# pse84 register map
Vendor: Cypress Semiconductor; Series: PSE84; File version: 1.0
CPU: CM33 r0p1, little endian, MPU, FPU, VTOR, 3 interrupt priority bits
Registers are 32-bit, read-write, reset 0x0 unless marked. A register's access mark holds for its fields unless they carry their own. Offsets are from the block's base; [hi:lo] are bit positions; lines under a group give offsets from that group; {n}, {i} and the like mark numbered series; 'fields as' and 'values as' point back to an identical list; <NAME> marks a mode.

## RTC — SRSS RTC Registers
Base 0x42420000
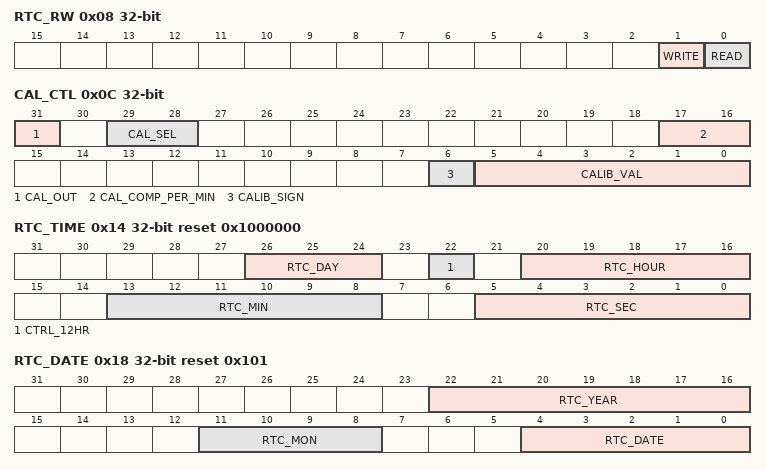
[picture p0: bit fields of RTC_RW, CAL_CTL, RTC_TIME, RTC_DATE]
0x08 RTC_RW — RTC Read Write register
  [1] WRITE — Write bit Only when this bit is set can the RTC registers be written to (otherwise writes are ignored). This bit cannot be set if the RTC is still busy with a previous update (see RTC_BUSY bit) or if the Read bit is set or getting set. The user writes to the RTC user registers, when the Write bit is cleared by the user then the user registers content is copied to the actual RTC registers. Only user RTC registers that were written to will get copied, others will not be affected. When the SECONDS field is updated then TICKS will also be reset (WDT is not affected). When the Write bit is cleared by a reset (brown out/DeepSleep) then the RTC update will be ignored/lost. Do not set the Write bit if the RTC if the RTC is still busy with a previous update (see RTC_BUSY). Do not set the Write bit at the same time that the Read bit is cleared.
  [0] READ — Read bit When this bit is set the RTC registers will be copied to user registers and frozen so that a coherent RTC value can safely be read. The RTC will keep on running. Do not set the read bit if the RTC is still busy with a previous update (see RTC_BUSY bit) or if the Write bit is set. Do not set the Read bit at the same time that the Write bit is cleared.
0x0C CAL_CTL — Oscillator calibration for absolute frequency
  [31] CAL_OUT — Output enable for wave signal for calibration. This allows calibration wave to be used to calculate required CALIB_VAL to be written.
  [29:28] CAL_SEL — Select calibration wave output signal
    0=CAL512 (512Hz wave, not affected by calibration setting (not supported for 50/60Hz input clock: CTL.PRESCALER!=0)); 1=RSVD (N/A); 2=CAL2 (2Hz wave, includes the effect of the calibration setting, (not supported for 50/60Hz input clock: CTL.PRESCALER!=0)); 3=CAL1 (1Hz wave, includes the effect of the calibration setting (supported for all input clocks))
  [17:16] CAL_COMP_PER_MIN — Select how many time calibration is performed per minute per step of 64 , each time a 64 step is added or substracted one unit 2/4/8/16*CALIB_VAL is substracted.
    0=Calibration of 64 each is performed twice per minute for 2*CALIB_VAL per hour; 1=Calibration of 64 each is performed four times per minute for 2*CALIB_VAL per hour; 2=Calibration of 64 each is performed eight times per minute for 2*CALIB_VAL per hour; 3=Ca6libration of 64 each is performed sixteen times per minute for 2*CALIB_VAL per hour
  [6] CALIB_SIGN — Calibration sign: 0= Negative sign: remove pulses (it takes more clock ticks to count one second) 1= Positive sign: add pulses (it takes less clock ticks to count one second)
  [5:0] CALIB_VAL — Calibration value for absolute frequency (at a fixed temperature). Each step causes 128 ticks to be added or removed each hour. Effectively that means that each step is 1.085ppm (= 128/(60*60*32,768)) when CAL_COMP_PER_MIN is set at default value. Positive values 0x01-0x3c (1..60) add pulses, negative values remove pulses, thus giving a range of +/-65.1 ppm (limited by 60 minutes per hour, not the range of this field) when CAL_COMP_PER_MIN is set at default value . Calibration is performed hourly, starting at 59 minutes and 59 seconds, and applied as 64 ticks every 30 seconds until there have been 2*CALIB_VAL adjustments when CAL_COMP_PER_MIN is set at default value .
0x10 STATUS ro
  [0] RTC_BUSY — Pending RTC write
0x14 RTC_TIME reset 0x1000000 — Calendar Seconds, Minutes, Hours, Day of Week
  [26:24] RTC_DAY — Calendar Day of the week, 1-7 It is up to the user to define the meaning of the values, but 1=Monday is recommended
  [22] CTRL_12HR — Select 12/24HR mode: 1=12HR, 0=24HR
  [20:16] RTC_HOUR — Calendar hours, value depending on 12/24HR mode 0=24HR: [20:16]=0-23 1=12HR: [20]:0=AM, 1=PM, [19:16]=1-12
  [13:8] RTC_MIN — Calendar minutes, 0-59
  [5:0] RTC_SEC — Calendar seconds, 0-59
0x18 RTC_DATE reset 0x101 — Calendar Day of Month, Month, Year
  [22:16] RTC_YEAR — Calendar year, 0-99
  [11:8] RTC_MON — Calendar Month, 1-12
  [4:0] RTC_DATE — Calendar Day of the Month, 1-31 Automatic Leap Year Correction
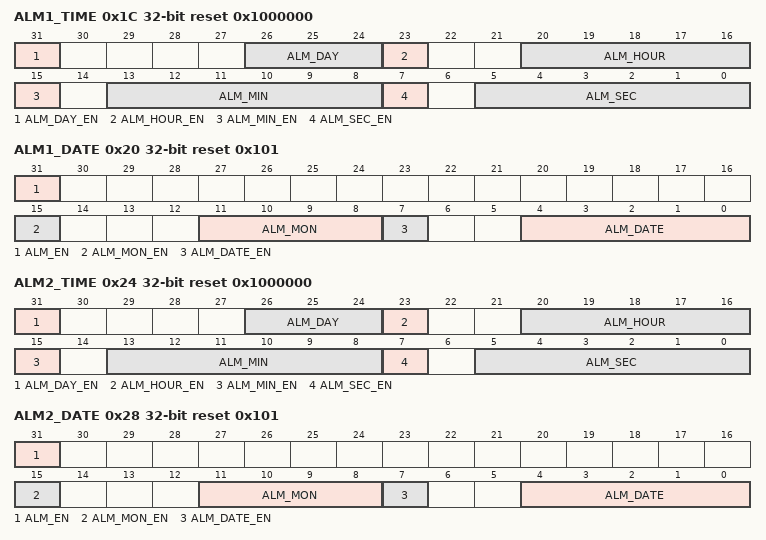
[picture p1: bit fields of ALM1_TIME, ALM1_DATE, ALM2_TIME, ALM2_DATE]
0x1C ALM1_TIME reset 0x1000000 — Alarm 1 Seconds, Minute, Hours, Day of Week
  [31] ALM_DAY_EN — Alarm Day of the Week enable: 0=ignore, 1=match
  [26:24] ALM_DAY — Alarm Day of the week, 1-7 It is up to the user to define the meaning of the values, but 1=Monday is recommended
  [23] ALM_HOUR_EN — Alarm hour enable: 0=ignore, 1=match
  [20:16] ALM_HOUR — Alarm hours, value depending on 12/24HR mode 24HR: [4:0]=0-23 12HR: [4]:0=AM, 1=PM, [3:0]=1-12
  [15] ALM_MIN_EN — Alarm minutes enable: 0=ignore, 1=match
  [13:8] ALM_MIN — Alarm minutes, 0-59
  [7] ALM_SEC_EN — Alarm second enable: 0=ignore, 1=match
  [5:0] ALM_SEC — Alarm seconds, 0-59
0x20 ALM1_DATE reset 0x101 — Alarm 1 Day of Month, Month
  [31] ALM_EN — Master enable for alarm 1. 0: Alarm 1 is disabled. Fields for date and time are ignored. 1: Alarm 1 is enabled. Alarm triggers whenever the new date and time matches all the enabled date and time fields, which can happen more than once depending on configuration. If none of the date and time fields are enabled, then this alarm triggers once every second.
  [15] ALM_MON_EN — Alarm Month enable: 0=ignore, 1=match
  [11:8] ALM_MON — Alarm Month, 1-12
  [7] ALM_DATE_EN — Alarm Day of the Month enable: 0=ignore, 1=match
  [4:0] ALM_DATE — Alarm Day of the Month, 1-31 Leap Year corrected
0x24 ALM2_TIME reset 0x1000000 — Alarm 2 Seconds, Minute, Hours, Day of Week
  fields as ALM1_TIME
0x28 ALM2_DATE reset 0x101 — Alarm 2 Day of Month, Month
  [31] ALM_EN — Master enable for alarm 2. 0: Alarm 2 is disabled. Fields for date and time are ignored. 1: Alarm 2 is enabled. Alarm triggers whenever the new date and time matches all the enabled date and time fields, which can happen more than once depending on configuration. If none of the date and time fields are enabled, then this alarm triggers once every second.
  [15] ALM_MON_EN — Alarm Month enable: 0=ignore, 1=match
  [11:8] ALM_MON — Alarm Month, 1-12
  [7] ALM_DATE_EN — Alarm Day of the Month enable: 0=ignore, 1=match
  [4:0] ALM_DATE — Alarm Day of the Month, 1-31 Leap Year corrected
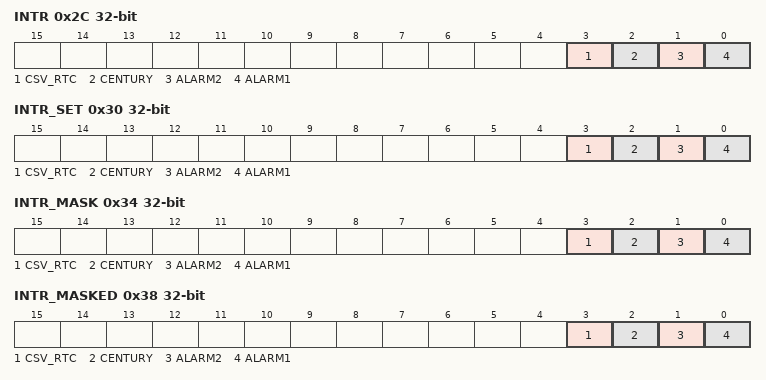
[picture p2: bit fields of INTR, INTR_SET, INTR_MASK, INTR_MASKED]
0x2C INTR — Interrupt request register
  [3] CSV_RTC — CSV_RTC Interrupt Request. This bit is set when RTCCLK is below or above the expected limit
  [2] CENTURY — Century overflow interrupt
  [1] ALARM2 — Alarm 2 Interrupt
  [0] ALARM1 — Alarm 1 Interrupt
0x30 INTR_SET — Interrupt set request register
  [3] CSV_RTC — Write with '1' to set corresponding bit in interrupt request register.
  [2] CENTURY — Write with '1' to set corresponding bit in interrupt request register.
  [1] ALARM2 — Write with '1' to set corresponding bit in interrupt request register.
  [0] ALARM1 — Write with '1' to set corresponding bit in interrupt request register.
0x34 INTR_MASK — Interrupt mask register
  [3] CSV_RTC — Mask bit for corresponding bit in interrupt request register.
  [2] CENTURY — Mask bit for corresponding bit in interrupt request register.
  [1] ALARM2 — Mask bit for corresponding bit in interrupt request register.
  [0] ALARM1 — Mask bit for corresponding bit in interrupt request register.
0x38 INTR_MASKED ro — Interrupt masked request register
  [3] CSV_RTC — Logical and of corresponding request and mask bits.
  [2] CENTURY — Logical and of corresponding request and mask bits.
  [1] ALARM2 — Logical and of corresponding request and mask bits.
  [0] ALARM1 — Logical and of corresponding request and mask bits.
0x48 RESET — RTC reset register
  [31] RESET — Writing 1 to this register resets the backup logic. Hardware clears it when the reset is complete. After setting this register, firmware should confirm it reads as 0 before attempting to write other backup registers.
0x90 CSV_RTC_REF_SEL — Select CSV Reference clock for RTC clock
  [1:0] RTC_REF_MUX — Selects a source for clock clk_ref_rtc. Note that not all products support all clock sources. Selecting a clock source that is not supported will result in undefined behavior. It takes four cycles of the originally selected clock to switch away from it. Do not disable the original clock during this time. Same clock sources are also souce for clk_rtc. Do not select the same clock.
    0=PILO (Precision internal low-speed oscillator, available in Active, DeepSleep, and Hibernate. (Product Specific)); 1=ILO (Internal Low frequency Oscillator, available in Active, DeepSleep, and Hibernate. (Product Specific)); 2=WCO (Watch-crystal oscillator input, available in Active, DeepSleep, and Hibernate. (Product Specific))
0x100 CSV_RTC group — CSV registers for clk_rtc clock
  0x00 CSV group — clk_bak Backup domain Clock Supervisor registers
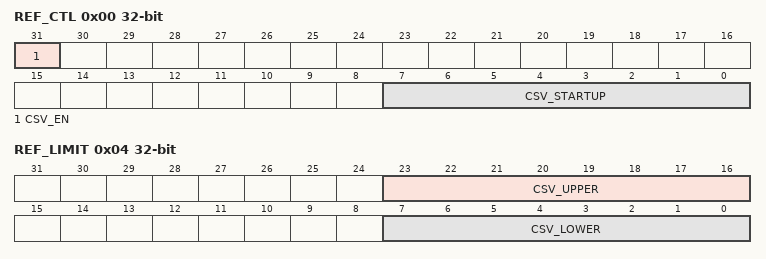
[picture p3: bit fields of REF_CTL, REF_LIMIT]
    0x00 REF_CTL — Clock Supervision Reference Control
      [31] CSV_EN — Enables clock supervision, both frequency and loss. CSV in Active domain: Clock supervision is reset during DeepSleep and Hibernate modes. When enabled it begins operating automatically after a DeepSleep wakeup, but it must be reconfigured after Hibernate wakeup. CSV in DeepSleep domain: Clock supervision is reset during Hibernate mode. It must be reconfigured after Hibernate wakeup. CSV in Backup domain: Clock supervision operates during Hibernate mode, can be configured to wake from Hibernate, and continues operating during reboot. A CSV error detection is reported to the Fault structure.
      [7:0] CSV_STARTUP — Startup delay time -1 (in reference clock cycles), after enable, from reference clock start to monitored clock start. At a minimum (both clocks running): STARTUP >= (PERIOD +3) * FREQ_RATIO - UPPER, with FREQ_RATIO = (Reference frequency / Monitored frequency) On top of that the actual clock startup delay and the margin for accuracy of both clocks must be added.
    0x04 REF_LIMIT — Clock Supervision Reference Limits
      [23:16] CSV_UPPER — Cycle time upper limit. Set the upper limit -1, in reference clock cycles, before (or same time) the next monitored clock event must happen. If a monitored clock event does not happen before this limit is reached, or does not happen at all (clock loss), a CSV error is detected.
      [7:0] CSV_LOWER — Cycle time lower limit. Set the lower limit -1, in reference clock cycles, before the next monitored clock event is allowed to happen. If a monitored clock event happens before this limit is reached a CSV error is detected. LOWER must be at least 1 less than UPPER. In case the clocks are asynchronous LOWER must be at least 3 less than UPPER.
    0x08 MON_CTL — Clock Supervision Monitor Control
      [7:0] CSV_PERIOD — Period time. Set the Period -1, in monitored clock cycles, before the next monitored clock event happens. PERIOD <= (UPPER+1) / FREQ_RATIO -1, with FREQ_RATIO = (Reference frequency / Monitored frequency) In case the clocks are asynchronous: PERIOD <= UPPER / FREQ_RATIO -1 Additionally margin must be added for accuracy of both clocks.
{0x1000+4i} BREG_SET0[{i}] (i=0..3) — Backup register region 0
  [31:0] BREG — Backup memory that contains application-specific data. Memory is retained on VDDD supply.
{0x1010+4i} BREG_SET1[{i}] (i=0..3) — Backup register region 1
  fields as BREG_SET0[0]
{0x1020+4i} BREG_SET2[{i}] (i=0..7) — Backup register region 2
  fields as BREG_SET0[0]
{0x1080+4i} BREG_SET3[{i}] (i=0..47) — Backup register region 3
  fields as BREG_SET0[0]
